AUTOSAR XML (schema 4-3-0)
package /ComponentTypes
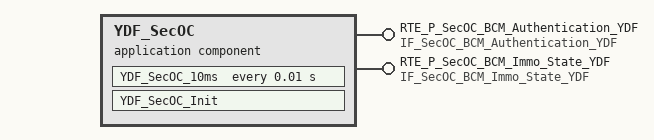
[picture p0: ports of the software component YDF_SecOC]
  application sw component type YDF_SecOC
    provide port RTE_P_SecOC_BCM_Authentication_YDF: nonqueued-sender-com-spec{data-element=BCM_Authentication_YDF, init-value=0}, provided-interface=IF_SecOC_BCM_Authentication_YDF
    provide port RTE_P_SecOC_BCM_Immo_State_YDF: nonqueued-sender-com-spec{data-element=BCM_Immo_State_YDF, init-value=0}, provided-interface=IF_SecOC_BCM_Immo_State_YDF
    behavior YDF_SecOC_InternalBehavior
      init event YDF_SecOC_InitEvent: start-on-event=YDF_SecOC_Init
      timing event TMT_YDF_SecOC10ms: start-on-event=YDF_SecOC_10ms, period=0.01
      runnable YDF_SecOC_10ms
        data-send-points:
          access SEND_RTE_P_SecOC_BCM_Authentication_YDF_BCM_Authentication_YDF: accessed-variable=RTE_P_SecOC_BCM_Authentication_YDF.BCM_Authentication_YDF
          access SEND_RTE_P_SecOC_BCM_Immo_State_YDF_BCM_Immo_State_YDF: accessed-variable=RTE_P_SecOC_BCM_Immo_State_YDF.BCM_Immo_State_YDF
      runnable YDF_SecOC_Init
  swc implementation YDF_SecOC_Implementation: behavior=YDF_SecOC_InternalBehavior
